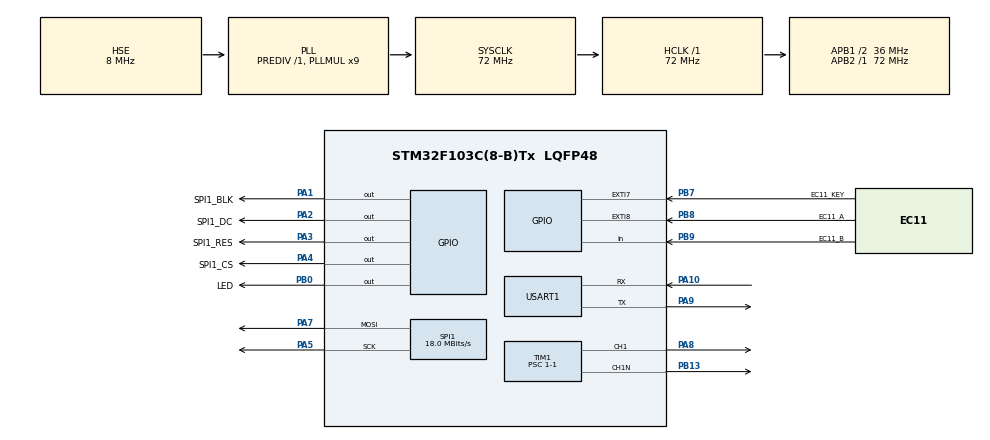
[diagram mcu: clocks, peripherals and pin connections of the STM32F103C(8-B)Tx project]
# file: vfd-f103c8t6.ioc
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Mcu.Family=STM32F1
Mcu.Name=STM32F103C(8-B)Tx
Mcu.Package=LQFP48
NVIC.EXTI9_5_IRQn=true\:0\:0\:false\:false\:true\:true\:true\:true
NVIC.PriorityGroup=NVIC_PRIORITYGROUP_4
NVIC.TIM1_UP_IRQn=true\:0\:0\:false\:false\:true\:true\:true\:true
NVIC.TIM4_IRQn=true\:0\:0\:false\:false\:true\:true\:true\:true
PA1.GPIO_Label=SPI1_BLK
PA1.PinState=GPIO_PIN_RESET
PA1.Signal=GPIO_Output
PA10.Mode=Asynchronous
PA10.Signal=USART1_RX
PA13.Mode=Serial_Wire
PA13.Signal=SYS_JTMS-SWDIO
PA14.Mode=Serial_Wire
PA14.Signal=SYS_JTCK-SWCLK
PA2.GPIO_Label=SPI1_DC
PA2.PinState=GPIO_PIN_SET
PA2.Signal=GPIO_Output
PA3.GPIO_Label=SPI1_RES
PA3.PinState=GPIO_PIN_SET
PA3.Signal=GPIO_Output
PA4.GPIO_Label=SPI1_CS
PA4.PinState=GPIO_PIN_SET
PA4.Signal=GPIO_Output
PA5.Mode=TX_Only_Simplex_Unidirect_Master
PA5.Signal=SPI1_SCK
PA7.Mode=TX_Only_Simplex_Unidirect_Master
PA7.Signal=SPI1_MOSI
PA8.Signal=S_TIM1_CH1
PA9.Mode=Asynchronous
PA9.Signal=USART1_TX
PB0.GPIO_Label=LED
PB0.Signal=GPIO_Output
PB13.Mode=PWM Generation1 CH1 CH1N
PB13.Signal=TIM1_CH1N
PB7.GPIO_Label=EC11_KEY
PB7.GPIO_ModeDefaultEXTI=GPIO_MODE_IT_FALLING
PB7.Signal=GPXTI7
PB8.GPIO_Label=EC11_A
PB8.GPIO_ModeDefaultEXTI=GPIO_MODE_IT_RISING_FALLING
PB8.Signal=GPXTI8
PB9.GPIO_Label=EC11_B
PB9.Signal=GPIO_Input
PD0-OSC_IN.Mode=HSE-External-Oscillator
PD0-OSC_IN.Signal=RCC_OSC_IN
PD1-OSC_OUT.Mode=HSE-External-Oscillator
PD1-OSC_OUT.Signal=RCC_OSC_OUT
ProjectManager.HeapSize=0x200
ProjectManager.StackSize=0x400
ProjectManager.TargetToolchain=Makefile
RCC.AHBFreq_Value=72000000
RCC.APB1CLKDivider=RCC_HCLK_DIV2
RCC.APB1Freq_Value=36000000
RCC.APB1TimFreq_Value=72000000
RCC.APB2Freq_Value=72000000
RCC.APB2TimFreq_Value=72000000
RCC.HCLKFreq_Value=72000000
RCC.PLLMUL=RCC_PLL_MUL9
RCC.PLLSourceVirtual=RCC_PLLSOURCE_HSE
RCC.SYSCLKFreq_VALUE=72000000
RCC.SYSCLKSource=RCC_SYSCLKSOURCE_PLLCLK
RCC.USBFreq_Value=72000000
SH.S_TIM1_CH1.0=TIM1_CH1,PWM Generation1 CH1 CH1N
SPI1.BaudRatePrescaler=SPI_BAUDRATEPRESCALER_4
SPI1.CalculateBaudRate=18.0 MBits/s
SPI1.Direction=SPI_DIRECTION_2LINES
SPI1.Mode=SPI_MODE_MASTER
SPI1.VirtualType=VM_MASTER
TIM1.AutoReloadPreload=TIM_AUTORELOAD_PRELOAD_ENABLE
TIM1.Channel-PWM\ Generation1\ CH1\ CH1N=TIM_CHANNEL_1
TIM1.Period=720-1
TIM1.Prescaler=1-1
TIM4.AutoReloadPreload=TIM_AUTORELOAD_PRELOAD_ENABLE
TIM4.Period=1000-1
TIM4.Prescaler=72-1
USART1.VirtualMode=VM_ASYNC
VP_TIM1_VS_ClockSourceINT.Mode=Internal
VP_TIM4_VS_ClockSourceINT.Mode=Internal
board=custom

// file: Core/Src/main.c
/* USER CODE BEGIN Header */
/**
  ******************************************************************************
  * @file           : main.c
  * @brief          : Main program body
  ******************************************************************************
  * @attention
  *
  * Copyright (c) 2024 STMicroelectronics.
  * All rights reserved.
  *
  * This software is licensed under terms that can be found in the LICENSE file
  * in the root directory of this software component.
  * If no LICENSE file comes with this software, it is provided AS-IS.
  *
  ******************************************************************************
  */
/* USER CODE END Header */
#include "main.h"
#include "spi.h"
#include "tim.h"
#include "usart.h"
#include "gpio.h"

/* USER CODE BEGIN Includes */
#include "retarget.h"
#include "lcd.h"
#include "lcd_printf.h"
#include "spwm.h"
#include "lcd_font.h"
#include "ui.h"
/* USER CODE END Includes */

/* USER CODE BEGIN PM */
uint16_t target_spwm_freq = 10; // 目标正弦波频率 使用整数代替浮点数 实际/=10
uint8_t spwm_freq_step = 10;    // 调整正弦波频率步进值 使用整数代替浮点数 实际/=10
/* USER CODE END PM */

void SystemClock_Config(void);

int main(void)
{

  /* MCU Configuration--------------------------------------------------------*/

  /* Reset of all peripherals, Initializes the Flash interface and the Systick. */
  HAL_Init();

  /* Configure the system clock */
  SystemClock_Config();

  /* Initialize all configured peripherals */
  MX_GPIO_Init();
  MX_SPI1_Init();
  MX_USART1_UART_Init();
  MX_TIM4_Init();
  MX_TIM1_Init();
  /* USER CODE BEGIN 2 */
    RetargetInit(&huart1);
    /* 初始化LCD */
    lcd_init(LCD_BLACK, LCD_WHITE);
    ui_print_nums(target_spwm_freq);
    /* 初始化SPWM */
    spwm_list = (uint16_t*) malloc(sizeof(uint16_t) * SPWM_LIST_MAX_SIZE);  // 动态分配内存
    spwm_set(target_spwm_freq);

  /* USER CODE END 2 */

  /* Infinite loop */
  while (1)
  {

  }
}

void SystemClock_Config(void)
{
  RCC_OscInitTypeDef RCC_OscInitStruct = {0};
  RCC_ClkInitTypeDef RCC_ClkInitStruct = {0};

  /** Initializes the RCC Oscillators according to the specified parameters
  * in the RCC_OscInitTypeDef structure.
  */
  RCC_OscInitStruct.OscillatorType = RCC_OSCILLATORTYPE_HSE;
  RCC_OscInitStruct.HSEState = RCC_HSE_ON;
  RCC_OscInitStruct.HSEPredivValue = RCC_HSE_PREDIV_DIV1;
  RCC_OscInitStruct.HSIState = RCC_HSI_ON;
  RCC_OscInitStruct.PLL.PLLState = RCC_PLL_ON;
  RCC_OscInitStruct.PLL.PLLSource = RCC_PLLSOURCE_HSE;
  RCC_OscInitStruct.PLL.PLLMUL = RCC_PLL_MUL9;
  if (HAL_RCC_OscConfig(&RCC_OscInitStruct) != HAL_OK)
  {
    Error_Handler();
  }

  /** Initializes the CPU, AHB and APB buses clocks
  */
  RCC_ClkInitStruct.ClockType = RCC_CLOCKTYPE_HCLK|RCC_CLOCKTYPE_SYSCLK
                              |RCC_CLOCKTYPE_PCLK1|RCC_CLOCKTYPE_PCLK2;
  RCC_ClkInitStruct.SYSCLKSource = RCC_SYSCLKSOURCE_PLLCLK;
  RCC_ClkInitStruct.AHBCLKDivider = RCC_SYSCLK_DIV1;
  RCC_ClkInitStruct.APB1CLKDivider = RCC_HCLK_DIV2;
  RCC_ClkInitStruct.APB2CLKDivider = RCC_HCLK_DIV1;

  if (HAL_RCC_ClockConfig(&RCC_ClkInitStruct, FLASH_LATENCY_2) != HAL_OK)
  {
    Error_Handler();
  }
}

void Error_Handler(void)
{
  __disable_irq();
  while (1)
  {
  }
}
